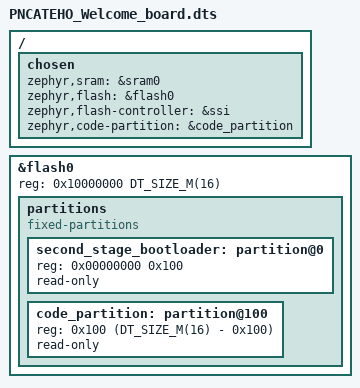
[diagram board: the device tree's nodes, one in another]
// Copyright (c) 2023 The ZMK Contributors
// SPDX-License-Identifier: MIT

/dts-v1/;

#include <raspberrypi/rpi_pico/rp2040.dtsi>

/ {
    chosen {
	zephyr,sram = &sram0;
        zephyr,flash = &flash0;
	zephyr,flash-controller = &ssi;
	zephyr,code-partition = &code_partition;
    };
};

&flash0 {
    reg = <0x10000000 DT_SIZE_M(16)>;

    partitions {
        compatible = "fixed-partitions";
        #address-cells = <1>;
        #size-cells = <1>;

        /* Reserved memory for the second stage bootloader */
        second_stage_bootloader: partition@0 {
            reg = <0x00000000 0x100>;
            read-only;
        };

        /*
         * Usable flash. Starts at 0x100, after the bootloader. The partition
         * size is 16MB minus the 0x100 bytes taken by the bootloader.
         */
        code_partition: partition@100 {
            reg = <0x100 (DT_SIZE_M(16) - 0x100)>;
            read-only;
        };
    };
};
